AUTOSAR XML (schema 4-0-3)
package /ComponentTypes
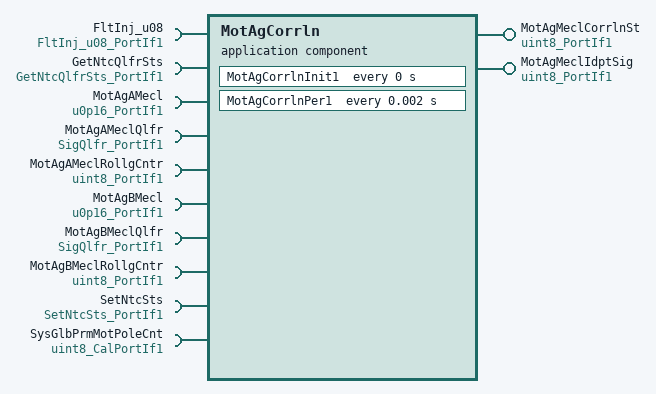
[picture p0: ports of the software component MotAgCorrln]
  application sw component type MotAgCorrln
    provide port MotAgMeclCorrlnSt: nonqueued-sender-com-spec{data-element=Val, init-value=3}, provided-interface=uint8_PortIf1
    provide port MotAgMeclIdptSig: nonqueued-sender-com-spec{data-element=Val, init-value=2}, provided-interface=uint8_PortIf1
    10 x require port:
      FltInj_u08: required-interface=FltInj_u08_PortIf1
      GetNtcQlfrSts: required-interface=GetNtcQlfrSts_PortIf1
      MotAgAMecl: nonqueued-receiver-com-spec{data-element=Val, filter=data-filter-type=ALWAYS, init-value=0}, required-interface=u0p16_PortIf1
      MotAgAMeclQlfr: nonqueued-receiver-com-spec{data-element=Val, filter=data-filter-type=ALWAYS, init-value=0}, required-interface=SigQlfr_PortIf1
      MotAgAMeclRollgCntr: nonqueued-receiver-com-spec{data-element=Val, filter=data-filter-type=ALWAYS, init-value=0}, required-interface=uint8_PortIf1
      MotAgBMecl: nonqueued-receiver-com-spec{data-element=Val, filter=data-filter-type=ALWAYS, init-value=0}, required-interface=u0p16_PortIf1
      MotAgBMeclQlfr: nonqueued-receiver-com-spec{data-element=Val, filter=data-filter-type=ALWAYS, init-value=0}, required-interface=SigQlfr_PortIf1
      MotAgBMeclRollgCntr: nonqueued-receiver-com-spec{data-element=Val, filter=data-filter-type=ALWAYS, init-value=0}, required-interface=uint8_PortIf1
      SetNtcSts: required-interface=SetNtcSts_PortIf1
      SysGlbPrmMotPoleCnt: parameter-require-com-spec{init-value=6, parameter=Val}, required-interface=uint8_CalPortIf1
    behavior MotAgCorrln_InternalBehavior: data-type-mapping=Nexteer
      ar-typed-per-instance-memorys:
        6 x data, all with sw-calibration-access=READ-ONLY:
          dMotAgCorrlnMotAgABOk: type=boolean
          MotAgCorrlnErrThd: type=u0p16
          MotAgCorrlnMotAgARollgCntPrev: type=uint8
          MotAgCorrlnMotAgAStallCntPrev: type=uint8
          MotAgCorrlnMotAgBRollgCntPrev: type=uint8
          MotAgCorrlnMotAgBStallCntPrev: type=uint8
      timing event MotAgCorrln_InitEvent: start-on-event=MotAgCorrlnInit1, period=0
      timing event TMT_MotAgCorrlnPer1: start-on-event=MotAgCorrlnPer1, period=0.002
      runnable MotAgCorrlnInit1
      runnable MotAgCorrlnPer1
        data-receive-point-by-arguments:
          8 x access:
            REC_MotAgAMecl_Val: accessed-variable=MotAgAMecl.Val
            REC_MotAgAMecl_Val_1: accessed-variable=MotAgAMecl.Val
            REC_MotAgAMeclQlfr_Val: accessed-variable=MotAgAMeclQlfr.Val
            REC_MotAgAMeclRollgCntr_Val: accessed-variable=MotAgAMeclRollgCntr.Val
            REC_MotAgBMecl_Val: accessed-variable=MotAgBMecl.Val
            REC_MotAgBMecl_Val_1: accessed-variable=MotAgBMecl.Val
            REC_MotAgBMeclQlfr_Val: accessed-variable=MotAgBMeclQlfr.Val
            REC_MotAgBMeclRollgCntr_Val: accessed-variable=MotAgBMeclRollgCntr.Val
        data-send-points:
          access SEND_MotAgMeclCorrlnSt_Val: accessed-variable=MotAgMeclCorrlnSt.Val
          access SEND_MotAgMeclCorrlnSt_Val_1: accessed-variable=MotAgMeclCorrlnSt.Val
          access SEND_MotAgMeclIdptSig_Val: accessed-variable=MotAgMeclIdptSig.Val
        4 x sync call, all with timeout=0:
          SC_FltInj_u08_Oper: operation=FltInj_u08.Oper
          SC_GetNtcQlfrSts_Oper: operation=GetNtcQlfrSts.Oper
          SC_GetNtcQlfrSts1_Oper: operation=GetNtcQlfrSts.Oper
          SC_SetNtcSts_Oper: operation=SetNtcSts.Oper
  swc implementation MotAgCorrln_Implementation: behavior=MotAgCorrln_InternalBehavior
    code-descriptors:
      code Default: artifact-descriptors=autosar-engineering-object={short-label=Default, category=SWSRC}
